# STM32L496AEI6 register map
File version: 1.0
Registers are 32-bit, access not given, reset 0x0 unless marked. A register's access mark holds for its fields unless they carry their own. Offsets are from the block's base; [hi:lo] are bit positions; {n}, {i} and the like mark numbered series; 'fields as' and 'values as' point back to an identical list.

## TIM6
Base 0x40001000
Same registers: TIM7 0x40001400
0x00 CR1
  [11] UIFREMA, [7] ARPE, [31:4] s, [3] OPM, [2] URS, [1] UDIS, [0] CEN
0x04 CR2
  [6:4] MMS, [31:0] s
0x0C DIER
  [8] UDE, [31:1] s, [0] UIE
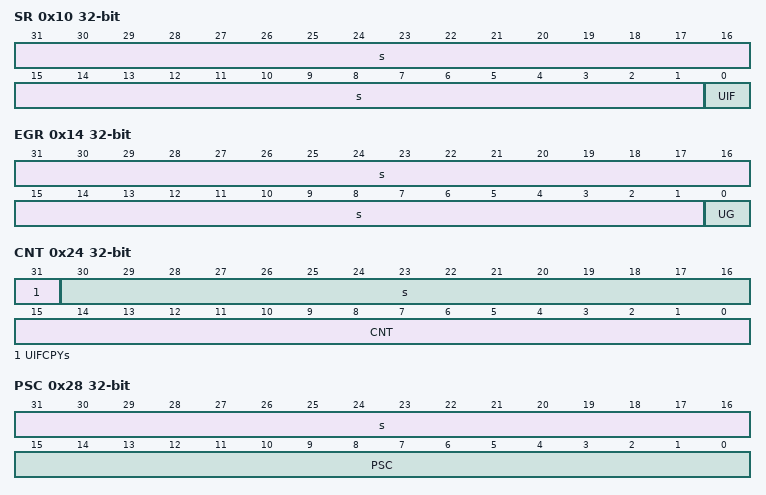
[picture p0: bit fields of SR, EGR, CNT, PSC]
0x10 SR
  [31:1] s, [0] UIF
0x14 EGR
  [31:1] s, [0] UG
0x24 CNT
  [31] UIFCPYs, [30:16] s, [15:0] CNT
0x28 PSC
  [31:16] s, [15:0] PSC
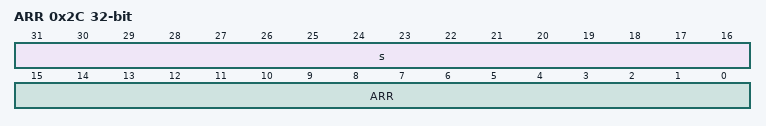
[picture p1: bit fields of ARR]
0x2C ARR
  [31:16] s, [15:0] ARR

## LCD
Base 0x40002400
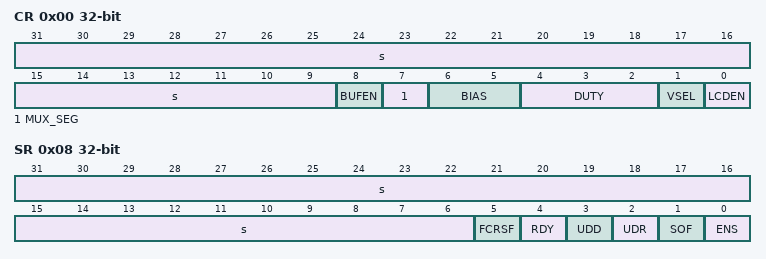
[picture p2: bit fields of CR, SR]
0x00 CR
  [31:9] s, [8] BUFEN, [7] MUX_SEG, [6:5] BIAS, [4:2] DUTY, [1] VSEL, [0] LCDEN
0x04 FCR
  [25:22] PS, [21:18] DIV, [17:16] BLINK, [15:13] BLINKF, [12:10] CC, [9:7] DEAD, [6:4] PON, [3] UDDIE, [31:2] s, [1] SOFIE, [0] HD
0x08 SR
  [31:6] s, [5] FCRSF, [4] RDY, [3] UDD, [2] UDR, [1] SOF, [0] ENS
0x0C CLR
  [3] UDDC, [1] SOFC, [31:0] s
{0x18+8i} RAM_COM{i} (i=0..7)

## RTC
Base 0x40002800
0x00 TR
  [22] PM, [21:20] HT, [19:16] HU, [14:12] MNT, [11:8] MNU, [31:7] s, [6:4] ST, [3:0] SU
0x04 DR
  [23:20] YT, [19:16] YU, [15:13] WDU, [12] MT, [11:8] MU, [31:6] s, [5:4] DT, [3:0] DU
0x08 CR
  [24] ITSE, [23] COE, [22:21] OSEL, [20] POL, [19] COSEL, [18] BKP, [17] SUB1H, [16] ADD1H, [15] TSIE, [14] WUTIE, [13] ALRBIE, [12] ALRAIE, [11] TSE, [10] WUTE, [9] ALRBE, [8] ALRAE, [31:7] s, [6] FMT, [5] BYPSHAD, [4] REFCKON, [3] TSEDGE, [2:0] WUCKSEL
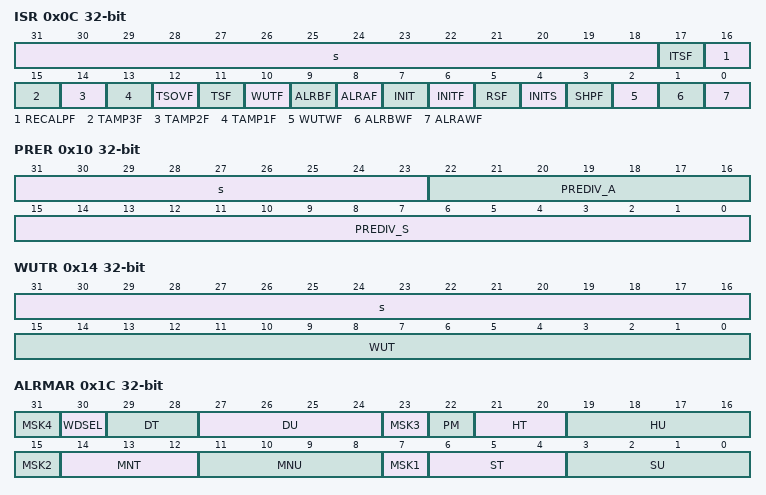
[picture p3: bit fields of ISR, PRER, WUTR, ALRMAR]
0x0C ISR
  [31:18] s, [17] ITSF, [16] RECALPF, [15] TAMP3F, [14] TAMP2F, [13] TAMP1F, [12] TSOVF, [11] TSF, [10] WUTF, [9] ALRBF, [8] ALRAF, [7] INIT, [6] INITF, [5] RSF, [4] INITS, [3] SHPF, [2] WUTWF, [1] ALRBWF, [0] ALRAWF
0x10 PRER
  [31:23] s, [22:16] PREDIV_A, [15:0] PREDIV_S
0x14 WUTR
  [31:16] s, [15:0] WUT
0x1C ALRMAR
  [8n-1] MSK{n} (n=1..4), [30] WDSEL, [29:28] DT, [27:24] DU, [22] PM, [21:20] HT, [19:16] HU, [14:12] MNT, [11:8] MNU, [6:4] ST, [3:0] SU
0x20 ALRMBR
  [31] MSK4, [30] WDSEL, [29:28] DT, [27:24] DU, [23] MSK3, [22] PM, [21:20] HT, [19:16] HU, [14:12] MNT, [11:8] MNU, [15:7] MSK2, [6:4] ST, [3:0] SU
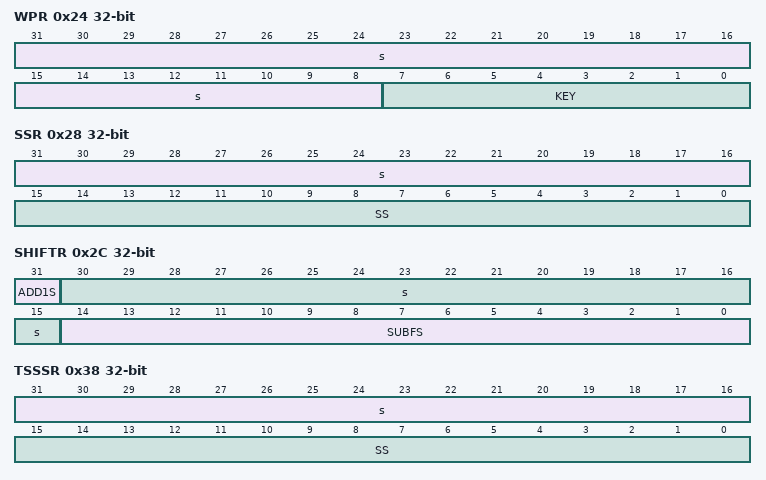
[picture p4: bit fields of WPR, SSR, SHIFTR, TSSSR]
0x24 WPR
  [31:8] s, [7:0] KEY
0x28 SSR
  [31:16] s, [15:0] SS
0x2C SHIFTR
  [31] ADD1S, [30:15] s, [14:0] SUBFS
0x30 TSTR
  fields as TR
0x34 TSDR
  [15:13] WDU, [12] MT, [11:8] MU, [31:6] s, [5:4] DT, [3:0] DU
0x38 TSSSR
  [31:16] s, [15:0] SS
0x3C CALR
  [15] CALP, [14] CALW8, [13] CALW16, [31:9] s, [8:0] CALM
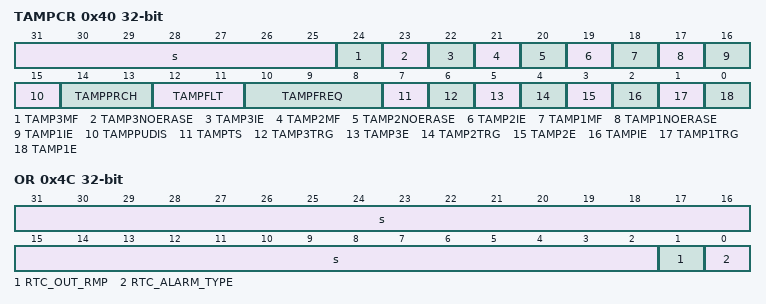
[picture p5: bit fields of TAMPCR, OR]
0x40 TAMPCR
  [31:25] s, [24] TAMP3MF, [23] TAMP3NOERASE, [22] TAMP3IE, [21] TAMP2MF, [20] TAMP2NOERASE, [19] TAMP2IE, [18] TAMP1MF, [17] TAMP1NOERASE, [16] TAMP1IE, [15] TAMPPUDIS, [14:13] TAMPPRCH, [12:11] TAMPFLT, [10:8] TAMPFREQ, [7] TAMPTS, [6] TAMP3TRG, [5] TAMP3E, [4] TAMP2TRG, [3] TAMP2E, [2] TAMPIE, [1] TAMP1TRG, [0] TAMP1E
0x44 ALRMASSR
  [27:24] MASKSS, [31:15] s, [14:0] SS
0x48 ALRMBSSR
  [27:24] MASKSS, [31:15] s, [14:0] SS
0x4C OR
  [31:2] s, [1] RTC_OUT_RMP, [0] RTC_ALARM_TYPE
{0x50+4i} BKP{i}R (i=0..31)
  [31:0] BKP

## WWDG
Base 0x40002C00
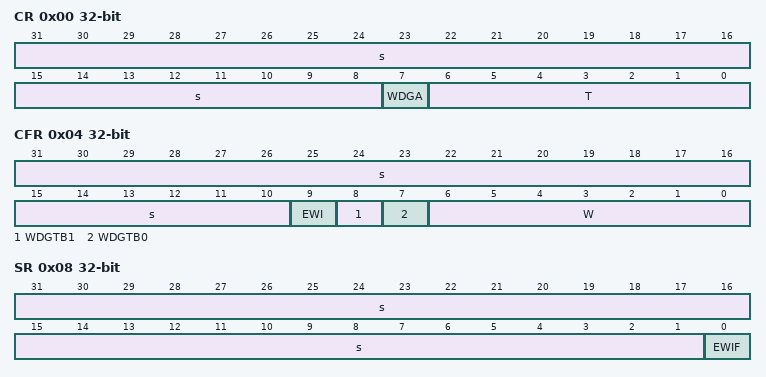
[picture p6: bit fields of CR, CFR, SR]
0x00 CR
  [31:8] s, [7] WDGA, [6:0] T
0x04 CFR
  [31:10] s, [9] EWI, [8] WDGTB1, [7] WDGTB0, [6:0] W
0x08 SR
  [31:1] s, [0] EWIF

## IWDG
Base 0x40003000
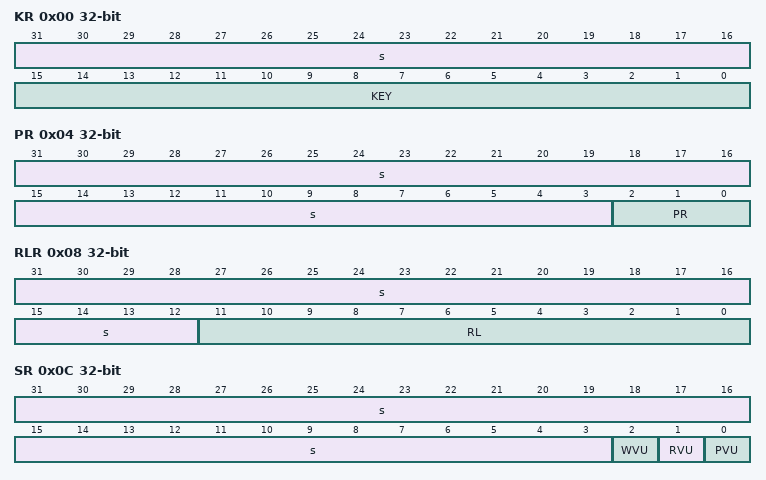
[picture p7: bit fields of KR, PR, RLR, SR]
0x00 KR
  [31:16] s, [15:0] KEY
0x04 PR
  [31:3] s, [2:0] PR
0x08 RLR
  [31:12] s, [11:0] RL
0x0C SR
  [31:3] s, [2] WVU, [1] RVU, [0] PVU
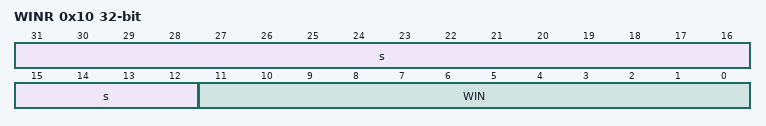
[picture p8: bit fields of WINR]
0x10 WINR
  [31:12] s, [11:0] WIN

## SPI2
Base 0x40003800
Same registers: SPI3 0x40003C00, SPI1 0x40013000
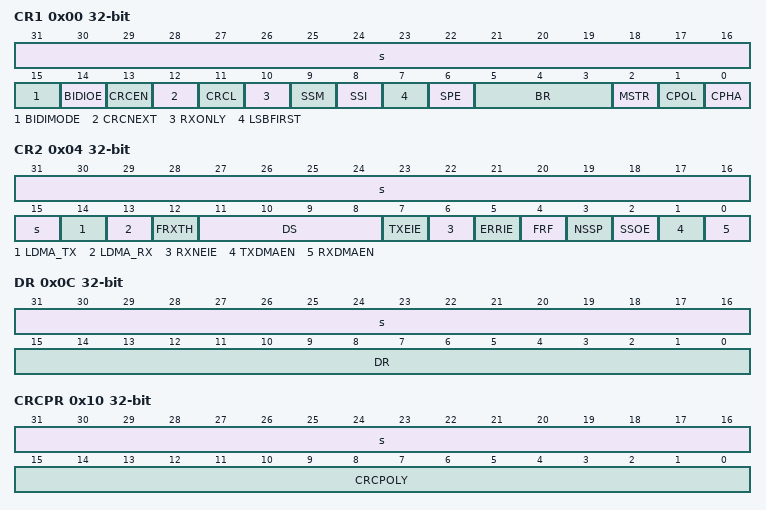
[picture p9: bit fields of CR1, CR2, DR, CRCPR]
0x00 CR1
  [31:16] s, [15] BIDIMODE, [14] BIDIOE, [13] CRCEN, [12] CRCNEXT, [11] CRCL, [10] RXONLY, [9] SSM, [8] SSI, [7] LSBFIRST, [6] SPE, [5:3] BR, [2] MSTR, [1] CPOL, [0] CPHA
0x04 CR2
  [31:15] s, [14] LDMA_TX, [13] LDMA_RX, [12] FRXTH, [11:8] DS, [7] TXEIE, [6] RXNEIE, [5] ERRIE, [4] FRF, [3] NSSP, [2] SSOE, [1] TXDMAEN, [0] RXDMAEN
0x08 SR
  [12:11] FTLVL, [10:9] FRLVL, [8] FRE, [7] BSY, [6] OVR, [5] MODF, [4] CRCERR, [31:2] s, [1] TXE, [0] RXNE
0x0C DR
  [31:16] s, [15:0] DR
0x10 CRCPR
  [31:16] s, [15:0] CRCPOLY
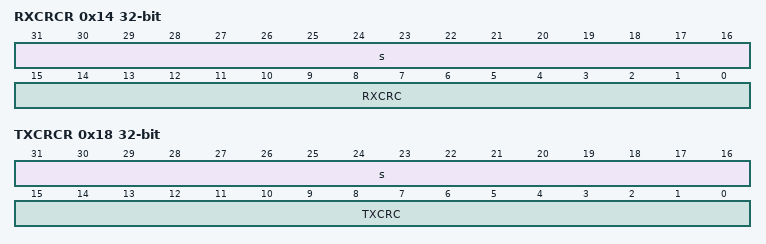
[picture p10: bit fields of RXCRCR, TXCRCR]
0x14 RXCRCR
  [31:16] s, [15:0] RXCRC
0x18 TXCRCR
  [31:16] s, [15:0] TXCRC
